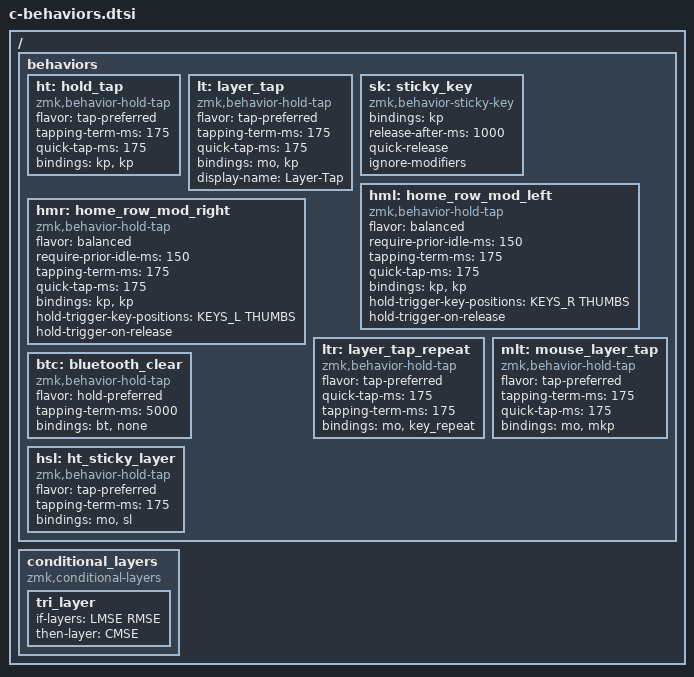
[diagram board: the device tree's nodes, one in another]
/ {
    behaviors {
        // Default behaviors
        ht: hold_tap {
            compatible = "zmk,behavior-hold-tap";
            #binding-cells = <2>;
            flavor = "tap-preferred";
            tapping-term-ms = <175>;
            quick-tap-ms = <175>;
            bindings = <&kp>, <&kp>;
        };
        lt: layer_tap {
            compatible = "zmk,behavior-hold-tap";
            #binding-cells = <2>;
            flavor = "tap-preferred";
            tapping-term-ms = <175>;
            quick-tap-ms = <175>;
            bindings = <&mo>, <&kp>;
            display-name = "Layer-Tap";
        };
        sk: sticky_key {
            compatible = "zmk,behavior-sticky-key";
            #binding-cells = <1>;
            bindings = <&kp>;
            release-after-ms = <1000>;
            quick-release;
            ignore-modifiers;
        };

        // Homerow modifiers
        hml: home_row_mod_left {
            compatible = "zmk,behavior-hold-tap";
            #binding-cells = <2>;
            flavor = "balanced";
            require-prior-idle-ms = <150>;
            tapping-term-ms = <175>;
            quick-tap-ms = <175>;
            bindings = <&kp>, <&kp>;
            hold-trigger-key-positions = <KEYS_R THUMBS>;
            hold-trigger-on-release;
        };
        hmr: home_row_mod_right {
            compatible = "zmk,behavior-hold-tap";
            #binding-cells = <2>;
            flavor = "balanced";
            require-prior-idle-ms = <150>;
            tapping-term-ms = <175>;
            quick-tap-ms = <175>;
            bindings = <&kp>, <&kp>;
            hold-trigger-key-positions = <KEYS_L THUMBS>;
            hold-trigger-on-release;
        };

        // Custom hold taps
        ltr: layer_tap_repeat {
            compatible = "zmk,behavior-hold-tap";
            #binding-cells = <2>;
            flavor = "tap-preferred";
            quick-tap-ms = <175>;
            tapping-term-ms = <175>;
            bindings = <&mo>, <&key_repeat>;
        };
        mlt: mouse_layer_tap {
            compatible = "zmk,behavior-hold-tap";
            #binding-cells = <2>;
            flavor = "tap-preferred";
            tapping-term-ms = <175>;
            quick-tap-ms = <175>;
            bindings = <&mo>, <&mkp>;
        };
        btc: bluetooth_clear {
            compatible = "zmk,behavior-hold-tap";
            #binding-cells = <2>;
            flavor = "hold-preferred";
            tapping-term-ms = <5000>;
            bindings = <&bt>, <&none>;
        };
        hsl: ht_sticky_layer {
            compatible = "zmk,behavior-hold-tap";
            #binding-cells = <2>;
            flavor = "tap-preferred";
            tapping-term-ms = <175>;
            bindings = <&mo>, <&sl>;
        };
    };
    conditional_layers {
        compatible = "zmk,conditional-layers";
        tri_layer {
            if-layers = <LMSE RMSE>;
            then-layer = <CMSE>;
        };
    };
};
